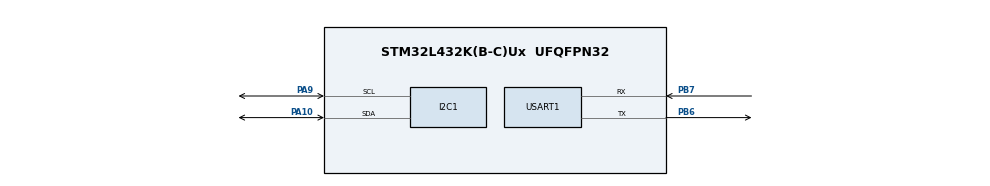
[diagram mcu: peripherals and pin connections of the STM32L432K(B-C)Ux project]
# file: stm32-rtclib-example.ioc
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FREERTOS.Mutexes01=i2c1_mutex,Dynamic,NULL,Available
FREERTOS.Tasks01=defaultTask,24,128,StartDefaultTask,Default,NULL,Dynamic,NULL,NULL
FREERTOS.configUSE_NEWLIB_REENTRANT=1
I2C1.Timing=0x00100D14
Mcu.Family=STM32L4
Mcu.Name=STM32L432K(B-C)Ux
Mcu.Package=UFQFPN32
NVIC.PriorityGroup=NVIC_PRIORITYGROUP_4
PA10.Mode=I2C
PA10.Signal=I2C1_SDA
PA9.Mode=I2C
PA9.Signal=I2C1_SCL
PB6.Mode=Asynchronous
PB6.Signal=USART1_TX
PB7.Mode=Asynchronous
PB7.Signal=USART1_RX
ProjectManager.HeapSize=0x200
ProjectManager.StackSize=0x400
ProjectManager.TargetToolchain=STM32CubeIDE
RCC.HSE_VALUE=8000000
RCC.HSI48_VALUE=48000000
RCC.HSI_VALUE=16000000
RCC.LSE_VALUE=32768
RCC.MSI_VALUE=4000000
RCC.VCOOutputFreq_Value=32000000
USART1.VirtualMode-Asynchronous=VM_ASYNC
VP_FREERTOS_VS_CMSIS_V2.Mode=CMSIS_V2
VP_RTC_VS_RTC_Activate.Mode=RTC_Enabled
VP_RTC_VS_RTC_Calendar.Mode=RTC_Calendar
board=custom

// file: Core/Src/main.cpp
/* USER CODE BEGIN Header */
/**
  ******************************************************************************
  * @file           : main.c
  * @brief          : Main program body
  ******************************************************************************
  * @attention
  *
  * Copyright (c) 2026 STMicroelectronics.
  * All rights reserved.
  *
  * This software is licensed under terms that can be found in the LICENSE file
  * in the root directory of this software component.
  * If no LICENSE file comes with this software, it is provided AS-IS.
  *
  ******************************************************************************
  */
/* USER CODE END Header */
#include "main.h"
#include "cmsis_os.h"

/* USER CODE BEGIN Includes */
#include <math.h>
#include <stdio.h>
#include <string.h>
#include "../../RTC-lib/inc/RTClib.h"

/* USER CODE END Includes */

I2C_HandleTypeDef hi2c1;

RTC_HandleTypeDef hrtc;

UART_HandleTypeDef huart1;

/* Definitions for defaultTask */
osThreadId_t defaultTaskHandle;
const osThreadAttr_t defaultTask_attributes = {
  .name = "defaultTask",
  .stack_size = 128 * 4,
  .priority = (osPriority_t) osPriorityNormal,
};
/* Definitions for i2c1_mutex */
osMutexId_t i2c1_mutexHandle;
const osMutexAttr_t i2c1_mutex_attributes = {
  .name = "i2c1_mutex"
};
/* USER CODE BEGIN PV */
RTC_DS1307 rtc(&hi2c1);

/* USER CODE END PV */

void SystemClock_Config(void);
static void MX_GPIO_Init(void);
static void MX_I2C1_Init(void);
static void MX_USART1_UART_Init(void);
static void MX_RTC_Init(void);
void StartDefaultTask(void *argument);

int main(void)
{

  /* MCU Configuration--------------------------------------------------------*/

  /* Reset of all peripherals, Initializes the Flash interface and the Systick. */
  HAL_Init();

  /* Configure the system clock */
  SystemClock_Config();

  /* Initialize all configured peripherals */
  MX_GPIO_Init();
  MX_I2C1_Init();
  MX_USART1_UART_Init();
  MX_RTC_Init();
  /* USER CODE BEGIN 2 */
  rtc.begin(DS1307_ADDR);
  //_now=rtc.now();

  //
  /* USER CODE END 2 */

  /* Init scheduler */
  osKernelInitialize();
  /* Create the mutex(es) */
  /* creation of i2c1_mutex */
  i2c1_mutexHandle = osMutexNew(&i2c1_mutex_attributes);

  /* Create the thread(s) */
  /* creation of defaultTask */
  defaultTaskHandle = osThreadNew(StartDefaultTask, NULL, &defaultTask_attributes);

  /* Start scheduler */
  osKernelStart();

  /* We should never get here as control is now taken by the scheduler */

  /* Infinite loop */
  while (1)
  {

  }
}

void SystemClock_Config(void)
{
  RCC_OscInitTypeDef RCC_OscInitStruct = {0};
  RCC_ClkInitTypeDef RCC_ClkInitStruct = {0};

  /** Configure the main internal regulator output voltage
  */
  if (HAL_PWREx_ControlVoltageScaling(PWR_REGULATOR_VOLTAGE_SCALE1) != HAL_OK)
  {
    Error_Handler();
  }

  /** Initializes the RCC Oscillators according to the specified parameters
  * in the RCC_OscInitTypeDef structure.
  */
  RCC_OscInitStruct.OscillatorType = RCC_OSCILLATORTYPE_LSI|RCC_OSCILLATORTYPE_MSI;
  RCC_OscInitStruct.LSIState = RCC_LSI_ON;
  RCC_OscInitStruct.MSIState = RCC_MSI_ON;
  RCC_OscInitStruct.MSICalibrationValue = 0;
  RCC_OscInitStruct.MSIClockRange = RCC_MSIRANGE_6;
  RCC_OscInitStruct.PLL.PLLState = RCC_PLL_NONE;
  if (HAL_RCC_OscConfig(&RCC_OscInitStruct) != HAL_OK)
  {
    Error_Handler();
  }

  /** Initializes the CPU, AHB and APB buses clocks
  */
  RCC_ClkInitStruct.ClockType = RCC_CLOCKTYPE_HCLK|RCC_CLOCKTYPE_SYSCLK
                              |RCC_CLOCKTYPE_PCLK1|RCC_CLOCKTYPE_PCLK2;
  RCC_ClkInitStruct.SYSCLKSource = RCC_SYSCLKSOURCE_MSI;
  RCC_ClkInitStruct.AHBCLKDivider = RCC_SYSCLK_DIV1;
  RCC_ClkInitStruct.APB1CLKDivider = RCC_HCLK_DIV1;
  RCC_ClkInitStruct.APB2CLKDivider = RCC_HCLK_DIV1;

  if (HAL_RCC_ClockConfig(&RCC_ClkInitStruct, FLASH_LATENCY_0) != HAL_OK)
  {
    Error_Handler();
  }
}

static void MX_I2C1_Init(void)
{

  hi2c1.Instance = I2C1;
  hi2c1.Init.Timing = 0x00100D14;
  hi2c1.Init.OwnAddress1 = 0;
  hi2c1.Init.AddressingMode = I2C_ADDRESSINGMODE_7BIT;
  hi2c1.Init.DualAddressMode = I2C_DUALADDRESS_DISABLE;
  hi2c1.Init.OwnAddress2 = 0;
  hi2c1.Init.OwnAddress2Masks = I2C_OA2_NOMASK;
  hi2c1.Init.GeneralCallMode = I2C_GENERALCALL_DISABLE;
  hi2c1.Init.NoStretchMode = I2C_NOSTRETCH_DISABLE;
  if (HAL_I2C_Init(&hi2c1) != HAL_OK)
  {
    Error_Handler();
  }

  /** Configure Analogue filter
  */
  if (HAL_I2CEx_ConfigAnalogFilter(&hi2c1, I2C_ANALOGFILTER_ENABLE) != HAL_OK)
  {
    Error_Handler();
  }

  /** Configure Digital filter
  */
  if (HAL_I2CEx_ConfigDigitalFilter(&hi2c1, 0) != HAL_OK)
  {
    Error_Handler();
  }

}

static void MX_RTC_Init(void)
{

  RTC_TimeTypeDef sTime = {0};
  RTC_DateTypeDef sDate = {0};

  /** Initialize RTC Only
  */
  hrtc.Instance = RTC;
  hrtc.Init.HourFormat = RTC_HOURFORMAT_24;
  hrtc.Init.AsynchPrediv = 127;
  hrtc.Init.SynchPrediv = 255;
  hrtc.Init.OutPut = RTC_OUTPUT_DISABLE;
  hrtc.Init.OutPutRemap = RTC_OUTPUT_REMAP_NONE;
  hrtc.Init.OutPutPolarity = RTC_OUTPUT_POLARITY_HIGH;
  hrtc.Init.OutPutType = RTC_OUTPUT_TYPE_OPENDRAIN;
  if (HAL_RTC_Init(&hrtc) != HAL_OK)
  {
    Error_Handler();
  }

  /** Initialize RTC and set the Time and Date
  */
  sTime.Hours = 0x0;
  sTime.Minutes = 0x0;
  sTime.Seconds = 0x0;
  sTime.DayLightSaving = RTC_DAYLIGHTSAVING_NONE;
  sTime.StoreOperation = RTC_STOREOPERATION_RESET;
  if (HAL_RTC_SetTime(&hrtc, &sTime, RTC_FORMAT_BCD) != HAL_OK)
  {
    Error_Handler();
  }
  sDate.WeekDay = RTC_WEEKDAY_MONDAY;
  sDate.Month = RTC_MONTH_JANUARY;
  sDate.Date = 0x1;
  sDate.Year = 0x0;

  if (HAL_RTC_SetDate(&hrtc, &sDate, RTC_FORMAT_BCD) != HAL_OK)
  {
    Error_Handler();
  }

}

static void MX_USART1_UART_Init(void)
{

  huart1.Instance = USART1;
  huart1.Init.BaudRate = 115200;
  huart1.Init.WordLength = UART_WORDLENGTH_8B;
  huart1.Init.StopBits = UART_STOPBITS_1;
  huart1.Init.Parity = UART_PARITY_NONE;
  huart1.Init.Mode = UART_MODE_TX_RX;
  huart1.Init.HwFlowCtl = UART_HWCONTROL_NONE;
  huart1.Init.OverSampling = UART_OVERSAMPLING_16;
  huart1.Init.OneBitSampling = UART_ONE_BIT_SAMPLE_DISABLE;
  huart1.AdvancedInit.AdvFeatureInit = UART_ADVFEATURE_NO_INIT;
  if (HAL_UART_Init(&huart1) != HAL_OK)
  {
    Error_Handler();
  }

}

static void MX_GPIO_Init(void)
{

  /* GPIO Ports Clock Enable */
  __HAL_RCC_GPIOA_CLK_ENABLE();
  __HAL_RCC_GPIOB_CLK_ENABLE();

}

/* USER CODE BEGIN 4 */
DateTime _now;
uint8_t charBuffer[255];
/* USER CODE END 4 */

void StartDefaultTask(void *argument)
{
  /* USER CODE BEGIN 5 */

	//rtc.adjust(DateTime(2026, 7, 30, 16,34, 0));
  /* Infinite loop */
  for(;;)
  {
	  _now=rtc.now();

									 /* Write temperature to Debug UART */
									 sprintf((char*)charBuffer,"%d:%d:%d",_now.hour(),_now.minute(),_now.second());
									 HAL_UART_Transmit(&huart1,charBuffer,strlen((char*)charBuffer),HAL_MAX_DELAY);
    osDelay(1000);
  }
  /* USER CODE END 5 */
}

void Error_Handler(void)
{
  __disable_irq();
  while (1)
  {
  }
}
